VERSION ""

NS_ :

BS_:

BU_: XXX

BO_ 129 NEW_MSG_1: 8 XXX

BO_ 1072 NEW_MSG_2: 8 XXX
 SG_ NEW_SIGNAL_1 : 0|8@1+ (0.0165107525,0) [0|255] "" XXX

BO_ 512 MSG_10: 8 XXX

BO_ 513 GAS: 8 XXX
 SG_ POT_RPM : 40|16@1+ (1,0) [0|8191] "" XXX
 SG_ NEW_SIGNAL_2 : 0|16@1+ (1,0) [0|65535] "" XXX
 SG_ NEW_SIGNAL_1 : 16|8@1+ (1,0) [0|255] "" XXX
 SG_ NEW_SIGNAL_3 : 32|16@1+ (1,0) [0|255] "" XXX
 SG_ IntSig1 : 24|16@1+ (1,0) [0|65535] "" XXX

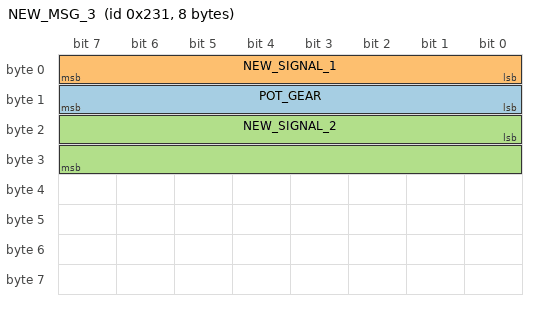
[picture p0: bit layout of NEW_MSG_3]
BO_ 561 NEW_MSG_3: 8 XXX
 SG_ POT_GEAR : 8|8@1+ (1,0) [0|255] "" XXX
 SG_ NEW_SIGNAL_1 : 0|8@1+ (1,0) [0|255] "" XXX
 SG_ NEW_SIGNAL_2 : 16|16@1+ (1,0) [0|65535] "" XXX

BO_ 1056 NEW_MSG_4: 8 XXX
 SG_ NEW_SIGNAL_1 : 0|8@1+ (1,0) [0|255] "" XXX
 SG_ NEW_SIGNAL_2 : 16|16@1+ (1,0) [0|255] "" XXX
